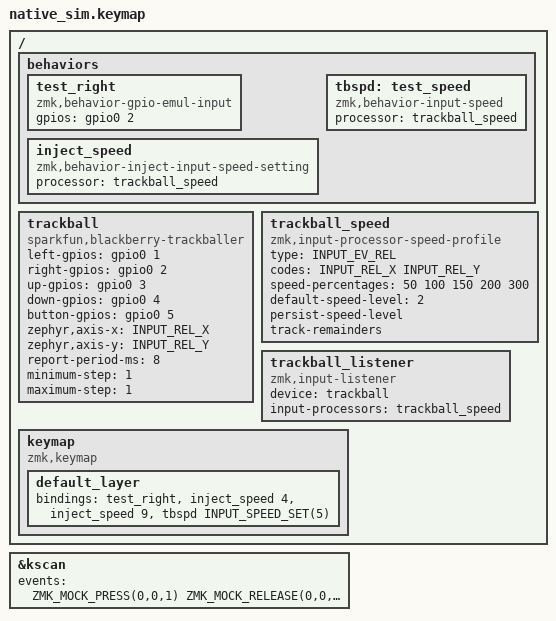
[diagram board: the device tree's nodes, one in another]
#include <zephyr/dt-bindings/gpio/gpio.h>
#include <zephyr/dt-bindings/input/input-event-codes.h>

#include <behaviors.dtsi>
#include <dt-bindings/zmk/input_speed.h>
#include <dt-bindings/zmk/kscan_mock.h>

/ {
    behaviors {
        test_right: test_right {
            compatible = "zmk,behavior-gpio-emul-input";
            #binding-cells = <0>;
            gpios = <&gpio0 2 GPIO_ACTIVE_HIGH>;
        };
        inject_speed: inject_speed {
            compatible = "zmk,behavior-inject-input-speed-setting";
            #binding-cells = <1>;
            processor = <&trackball_speed>;
        };
        tbspd: test_speed {
            compatible = "zmk,behavior-input-speed";
            #binding-cells = <2>;
            processor = <&trackball_speed>;
        };
    };

    trackball: trackball {
        compatible = "sparkfun,blackberry-trackballer";
        left-gpios = <&gpio0 1 GPIO_ACTIVE_HIGH>;
        right-gpios = <&gpio0 2 GPIO_ACTIVE_HIGH>;
        up-gpios = <&gpio0 3 GPIO_ACTIVE_HIGH>;
        down-gpios = <&gpio0 4 GPIO_ACTIVE_HIGH>;
        button-gpios = <&gpio0 5 GPIO_ACTIVE_HIGH>;
        zephyr,axis-x = <INPUT_REL_X>;
        zephyr,axis-y = <INPUT_REL_Y>;
        report-period-ms = <8>;
        minimum-step = <1>;
        maximum-step = <1>;
    };

    trackball_speed: trackball_speed {
        compatible = "zmk,input-processor-speed-profile";
        #input-processor-cells = <0>;
        type = <INPUT_EV_REL>;
        codes = <INPUT_REL_X INPUT_REL_Y>;
        speed-percentages = <50 100 150 200 300>;
        default-speed-level = <2>;
        persist-speed-level;
        track-remainders;
    };

    trackball_listener: trackball_listener {
        compatible = "zmk,input-listener";
        device = <&trackball>;
        input-processors = <&trackball_speed>;
    };

    keymap {
        compatible = "zmk,keymap";
        default_layer {
            bindings = <
                &test_right
                &inject_speed 4
                &inject_speed 9
                &tbspd INPUT_SPEED_SET(5)
            >;
        };
    };
};

&kscan {
    events = <
        /* No stored value: use default level 2. */
        ZMK_MOCK_PRESS(0,0,1)
        ZMK_MOCK_RELEASE(0,0,20)

        /* A valid stored value is restored. */
        ZMK_MOCK_PRESS(0,1,1)
        ZMK_MOCK_RELEASE(0,1,1)
        ZMK_MOCK_PRESS(0,0,1)
        ZMK_MOCK_RELEASE(0,0,20)

        /* An out-of-range stored value falls back to default level 2. */
        ZMK_MOCK_PRESS(0,2,1)
        ZMK_MOCK_RELEASE(0,2,1)
        ZMK_MOCK_PRESS(0,0,1)
        ZMK_MOCK_RELEASE(0,0,20)

        /* A keymap change is saved after the debounce interval. */
        ZMK_MOCK_PRESS(0,3,1)
        ZMK_MOCK_RELEASE(0,3,20)
        ZMK_MOCK_PRESS(0,0,1)
        ZMK_MOCK_RELEASE(0,0,20)
    >;
};
